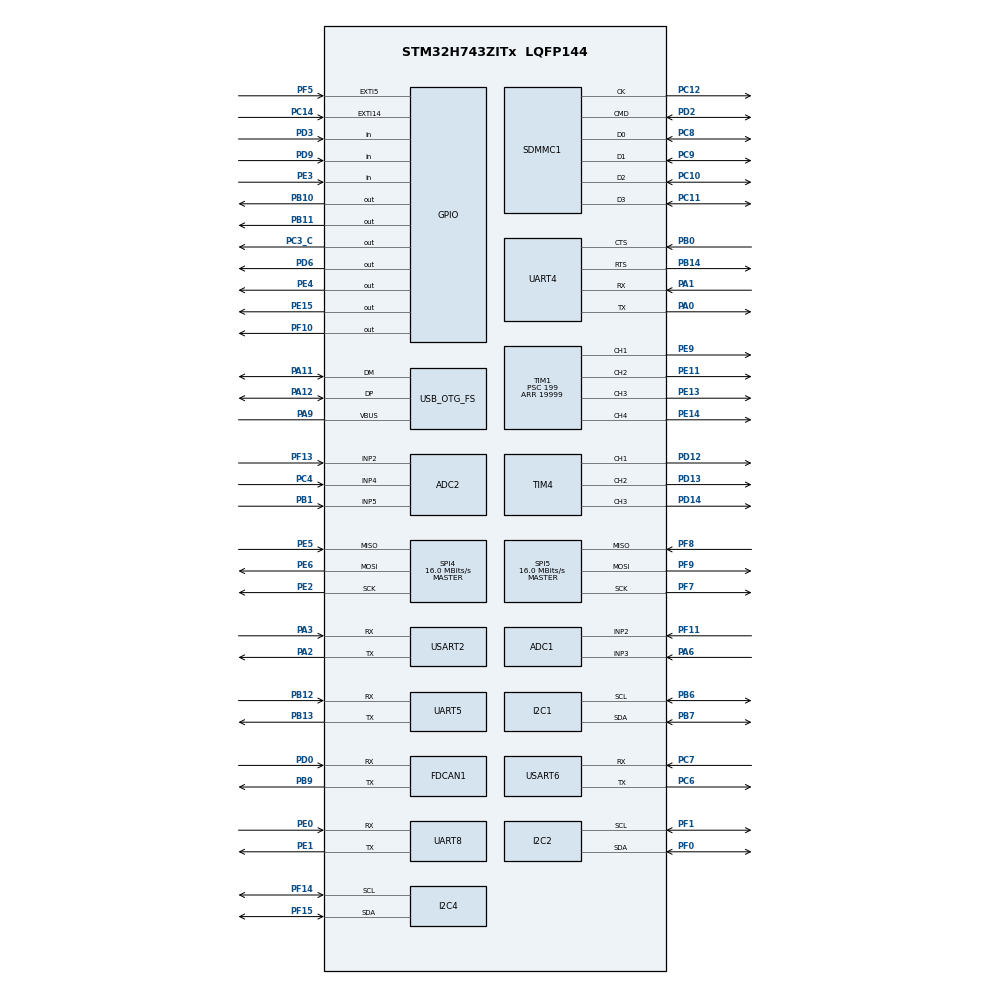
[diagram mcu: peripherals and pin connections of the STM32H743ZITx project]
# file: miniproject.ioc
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ADC1.Channel-3\#ChannelRegularConversion=ADC_CHANNEL_2
ADC1.ClockPrescaler=ADC_CLOCK_ASYNC_DIV4
ADC1.NbrOfConversionFlag=1
ADC1.OffsetNumber-3\#ChannelRegularConversion=ADC_OFFSET_NONE
ADC1.OffsetSignedSaturation-3\#ChannelRegularConversion=DISABLE
ADC1.Rank-3\#ChannelRegularConversion=1
ADC1.SamplingTime-3\#ChannelRegularConversion=ADC_SAMPLETIME_1CYCLE_5
ADC1.master=1
ADC2.Channel-0\#ChannelRegularConversion=ADC_CHANNEL_2
ADC2.ClockPrescaler=ADC_CLOCK_ASYNC_DIV4
ADC2.NbrOfConversionFlag=1
ADC2.OffsetNumber-0\#ChannelRegularConversion=ADC_OFFSET_NONE
ADC2.OffsetSignedSaturation-0\#ChannelRegularConversion=DISABLE
ADC2.Rank-0\#ChannelRegularConversion=1
ADC2.SamplingTime-0\#ChannelRegularConversion=ADC_SAMPLETIME_1CYCLE_5
CORTEX_M7.default_mode_Activation=1
FDCAN1.CalculateBaudRateNominal=1041666
FDCAN1.CalculateTimeBitNominal=960
FDCAN1.CalculateTimeQuantumNominal=320.0
I2C1.Timing=0x00707CBB
I2C2.Timing=0x00707CBB
I2C4.Timing=0x00707CBB
Mcu.Family=STM32H7
Mcu.Name=STM32H743ZITx
Mcu.Package=LQFP144
NVIC.PriorityGroup=NVIC_PRIORITYGROUP_4
PA0.Mode=Asynchronous
PA0.Signal=UART4_TX
PA1.Mode=Asynchronous
PA1.Signal=UART4_RX
PA11.Mode=Device_Only
PA11.Signal=USB_OTG_FS_DM
PA12.Mode=Device_Only
PA12.Signal=USB_OTG_FS_DP
PA13\ (JTMS/SWDIO).Mode=Trace_Asynchronous_SW
PA13\ (JTMS/SWDIO).Signal=DEBUG_JTMS-SWDIO
PA14\ (JTCK/SWCLK).Mode=Trace_Asynchronous_SW
PA14\ (JTCK/SWCLK).Signal=DEBUG_JTCK-SWCLK
PA2.Mode=Asynchronous
PA2.Signal=USART2_TX
PA3.Mode=Asynchronous
PA3.Signal=USART2_RX
PA6.Signal=ADCx_INP3
PA9.Mode=Activate_VBUS
PA9.Signal=USB_OTG_FS_VBUS
PB0.Mode=CTS_RTS
PB0.Signal=UART4_CTS
PB1.Signal=ADCx_INP5
PB10.Signal=GPIO_Output
PB11.Signal=GPIO_Output
PB12.Mode=Asynchronous
PB12.Signal=UART5_RX
PB13.Mode=Asynchronous
PB13.Signal=UART5_TX
PB14.Mode=CTS_RTS
PB14.Signal=UART4_RTS
PB3\ (JTDO/TRACESWO).Mode=Trace_Asynchronous_SW
PB3\ (JTDO/TRACESWO).Signal=DEBUG_JTDO-SWO
PB6.Mode=I2C
PB6.Signal=I2C1_SCL
PB7.Mode=I2C
PB7.Signal=I2C1_SDA
PB9.Mode=FDCAN_Activate
PB9.Signal=FDCAN1_TX
PC10.Mode=SD_4_bits_Wide_bus
PC10.Signal=SDMMC1_D2
PC11.Mode=SD_4_bits_Wide_bus
PC11.Signal=SDMMC1_D3
PC12.Mode=SD_4_bits_Wide_bus
PC12.Signal=SDMMC1_CK
PC14-OSC32_IN\ (OSC32_IN).Signal=GPXTI14
PC3_C.Signal=GPIO_Output
PC4.Signal=ADCx_INP4
PC6.Mode=Asynchronous
PC6.Signal=USART6_TX
PC7.Mode=Asynchronous
PC7.Signal=USART6_RX
PC8.Mode=SD_4_bits_Wide_bus
PC8.Signal=SDMMC1_D0
PC9.Mode=SD_4_bits_Wide_bus
PC9.Signal=SDMMC1_D1
PD0.Mode=FDCAN_Activate
PD0.Signal=FDCAN1_RX
PD12.Signal=S_TIM4_CH1
PD13.Signal=S_TIM4_CH2
PD14.Signal=S_TIM4_CH3
PD2.Mode=SD_4_bits_Wide_bus
PD2.Signal=SDMMC1_CMD
PD3.Signal=GPIO_Input
PD6.Signal=GPIO_Output
PD9.Signal=GPIO_Input
PE0.Mode=Asynchronous
PE0.Signal=UART8_RX
PE1.Mode=Asynchronous
PE1.Signal=UART8_TX
PE11.Signal=S_TIM1_CH2
PE13.Signal=S_TIM1_CH3
PE14.Signal=S_TIM1_CH4
PE15.Signal=GPIO_Output
PE2.Mode=Full_Duplex_Master
PE2.Signal=SPI4_SCK
PE3.Signal=GPIO_Input
PE4.Signal=GPIO_Output
PE5.Mode=Full_Duplex_Master
PE5.Signal=SPI4_MISO
PE6.Mode=Full_Duplex_Master
PE6.Signal=SPI4_MOSI
PE9.Signal=S_TIM1_CH1
PF0.Mode=I2C
PF0.Signal=I2C2_SDA
PF1.Mode=I2C
PF1.Signal=I2C2_SCL
PF10.Signal=GPIO_Output
PF11.Mode=IN2-Single-Ended
PF11.Signal=ADC1_INP2
PF13.Mode=IN2-Single-Ended
PF13.Signal=ADC2_INP2
PF14.Mode=I2C
PF14.Signal=I2C4_SCL
PF15.Mode=I2C
PF15.Signal=I2C4_SDA
PF5.Signal=GPXTI5
PF7.Mode=Full_Duplex_Master
PF7.Signal=SPI5_SCK
PF8.Mode=Full_Duplex_Master
PF8.Signal=SPI5_MISO
PF9.Mode=Full_Duplex_Master
PF9.Signal=SPI5_MOSI
PH0-OSC_IN\ (PH0).Mode=HSE-External-Oscillator
PH0-OSC_IN\ (PH0).Signal=RCC_OSC_IN
PH1-OSC_OUT\ (PH1).Mode=HSE-External-Oscillator
PH1-OSC_OUT\ (PH1).Signal=RCC_OSC_OUT
ProjectManager.HeapSize=0x200
ProjectManager.StackSize=0x400
ProjectManager.TargetToolchain=STM32CubeIDE
RCC.ADCFreq_Value=75000000
RCC.APB1Freq_Value=32000000
RCC.APB2Freq_Value=32000000
RCC.APB3Freq_Value=64000000
RCC.APB4Freq_Value=32000000
RCC.CortexFreq_Value=64000000
RCC.D2PPRE1=RCC_APB1_DIV2
RCC.D2PPRE2=RCC_APB2_DIV2
RCC.D3PPRE=RCC_APB4_DIV2
RCC.DIVM1=2
RCC.DIVM2=2
RCC.DIVN1=12
RCC.DIVN2=12
RCC.DIVQ1=3
RCC.HCLKFreq_Value=64000000
RCC.PLL2FRACN=0
RCC.PLL3FRACN=0
RCC.PLLFRACN=0
RCC.SYSCLKFreq_VALUE=64000000
RCC.USBFreq_Value=50000000
SH.ADCx_INP3.0=ADC1_INP3,IN3-Single-Ended
SH.ADCx_INP4.0=ADC2_INP4,IN4-Single-Ended
SH.ADCx_INP5.0=ADC2_INP5,IN5-Single-Ended
SH.S_TIM1_CH1.0=TIM1_CH1,PWM Generation1 CH1
SH.S_TIM1_CH2.0=TIM1_CH2,PWM Generation2 CH2
SH.S_TIM1_CH3.0=TIM1_CH3,PWM Generation3 CH3
SH.S_TIM1_CH4.0=TIM1_CH4,PWM Generation4 CH4
SH.S_TIM4_CH1.0=TIM4_CH1,PWM Generation1 CH1
SH.S_TIM4_CH2.0=TIM4_CH2,PWM Generation2 CH2
SH.S_TIM4_CH3.0=TIM4_CH3,PWM Generation3 CH3
SPI4.CalculateBaudRate=16.0 MBits/s
SPI4.Direction=SPI_DIRECTION_2LINES
SPI4.Mode=SPI_MODE_MASTER
SPI4.VirtualType=VM_MASTER
SPI5.CalculateBaudRate=16.0 MBits/s
SPI5.Direction=SPI_DIRECTION_2LINES
SPI5.Mode=SPI_MODE_MASTER
SPI5.VirtualType=VM_MASTER
TIM1.AutoReloadPreload=TIM_AUTORELOAD_PRELOAD_ENABLE
TIM1.Channel-PWM\ Generation1\ CH1=TIM_CHANNEL_1
TIM1.Channel-PWM\ Generation2\ CH2=TIM_CHANNEL_2
TIM1.Channel-PWM\ Generation3\ CH3=TIM_CHANNEL_3
TIM1.Channel-PWM\ Generation4\ CH4=TIM_CHANNEL_4
TIM1.Period=19999
TIM1.Prescaler=199
TIM1.Pulse-PWM\ Generation2\ CH2=1000
TIM1.Pulse-PWM\ Generation3\ CH3=1000
TIM1.Pulse-PWM\ Generation4\ CH4=1000
TIM4.Channel-PWM\ Generation1\ CH1=TIM_CHANNEL_1
TIM4.Channel-PWM\ Generation2\ CH2=TIM_CHANNEL_2
TIM4.Channel-PWM\ Generation3\ CH3=TIM_CHANNEL_3
TIM4.OCPolarity_1=TIM_OCPOLARITY_LOW
TIM4.OCPolarity_2=TIM_OCPOLARITY_LOW
TIM4.OCPolarity_3=TIM_OCPOLARITY_LOW
UART8.RxPinLevelInvertParam=UART_ADVFEATURE_RXINV_DISABLE
USART2.VirtualMode-Asynchronous=VM_ASYNC
USART6.VirtualMode-Asynchronous=VM_ASYNC
USB_OTG_FS.VirtualMode=Device_Only
VP_MEMORYMAP_VS_MEMORYMAP.Mode=CurAppReg
VP_TIM1_VS_ClockSourceINT.Mode=Internal
VP_TIM4_VS_ClockSourceINT.Mode=Internal
board=custom

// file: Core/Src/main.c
/* USER CODE BEGIN Header */
/**
  ******************************************************************************
  * @file           : main.c
  * @brief          : Main program body
  ******************************************************************************
  * @attention
  *
  * Copyright (c) 2026 STMicroelectronics.
  * All rights reserved.
  *
  * This software is licensed under terms that can be found in the LICENSE file
  * in the root directory of this software component.
  * If no LICENSE file comes with this software, it is provided AS-IS.
  *
  ******************************************************************************
  */
/* USER CODE END Header */
#include "aquila.h"
#include "main.h"

ADC_HandleTypeDef hadc1;
ADC_HandleTypeDef hadc2;

FDCAN_HandleTypeDef hfdcan1;

I2C_HandleTypeDef hi2c1;
I2C_HandleTypeDef hi2c2;
I2C_HandleTypeDef hi2c4;

SD_HandleTypeDef hsd1;

SPI_HandleTypeDef hspi4;
SPI_HandleTypeDef hspi5;

TIM_HandleTypeDef htim1;
TIM_HandleTypeDef htim4;

UART_HandleTypeDef huart4;
UART_HandleTypeDef huart5;
UART_HandleTypeDef huart8;
UART_HandleTypeDef huart2;
UART_HandleTypeDef huart6;

PCD_HandleTypeDef hpcd_USB_OTG_FS;

void SystemClock_Config(void);
void PeriphCommonClock_Config(void);
static void MPU_Config(void);
static void MX_GPIO_Init(void);
static void MX_USB_OTG_FS_PCD_Init(void);
static void MX_I2C1_Init(void);
static void MX_SDMMC1_SD_Init(void);
static void MX_UART4_Init(void);
static void MX_UART5_Init(void);
static void MX_ADC1_Init(void);
static void MX_I2C2_Init(void);
static void MX_TIM4_Init(void);
static void MX_I2C4_Init(void);
static void MX_TIM1_Init(void);
static void MX_FDCAN1_Init(void);
static void MX_SPI4_Init(void);
static void MX_SPI5_Init(void);
static void MX_UART8_Init(void);
static void MX_ADC2_Init(void);
static void MX_USART2_UART_Init(void);
static void MX_USART6_UART_Init(void);

int main(void)
{

  /* MPU Configuration--------------------------------------------------------*/
  MPU_Config();

  /* MCU Configuration--------------------------------------------------------*/

  /* Reset of all peripherals, Initializes the Flash interface and the Systick. */
  HAL_Init();

  /* Configure the system clock */
  SystemClock_Config();

  /* Configure the peripherals common clocks */
  PeriphCommonClock_Config();

  /* Initialize all configured peripherals */
  MX_GPIO_Init();
  MX_USB_OTG_FS_PCD_Init();
  MX_I2C1_Init();
  MX_SDMMC1_SD_Init();
  MX_UART4_Init();
  MX_UART5_Init();
  MX_ADC1_Init();
  MX_I2C2_Init();
  MX_TIM4_Init();
  MX_I2C4_Init();
  MX_TIM1_Init();
  MX_FDCAN1_Init();
  MX_SPI4_Init();
  MX_SPI5_Init();
  MX_UART8_Init();
  MX_ADC2_Init();
  MX_USART2_UART_Init();
  MX_USART6_UART_Init();
  /* USER CODE BEGIN 2 */
  Aquila_Init();
  /* USER CODE END 2 */

  /* Infinite loop */
  while (1)
  {
	  Aquila_Run();
  }
}

void SystemClock_Config(void)
{
  RCC_OscInitTypeDef RCC_OscInitStruct = {0};
  RCC_ClkInitTypeDef RCC_ClkInitStruct = {0};

  /** Supply configuration update enable
  */
  HAL_PWREx_ConfigSupply(PWR_LDO_SUPPLY);

  /** Configure the main internal regulator output voltage
  */
  __HAL_PWR_VOLTAGESCALING_CONFIG(PWR_REGULATOR_VOLTAGE_SCALE3);

  while(!__HAL_PWR_GET_FLAG(PWR_FLAG_VOSRDY)) {}

  /** Initializes the RCC Oscillators according to the specified parameters
  * in the RCC_OscInitTypeDef structure.
  */
  RCC_OscInitStruct.OscillatorType = RCC_OSCILLATORTYPE_HSI|RCC_OSCILLATORTYPE_HSE;
  RCC_OscInitStruct.HSEState = RCC_HSE_ON;
  RCC_OscInitStruct.HSIState = RCC_HSI_DIV1;
  RCC_OscInitStruct.HSICalibrationValue = RCC_HSICALIBRATION_DEFAULT;
  RCC_OscInitStruct.PLL.PLLState = RCC_PLL_ON;
  RCC_OscInitStruct.PLL.PLLSource = RCC_PLLSOURCE_HSE;
  RCC_OscInitStruct.PLL.PLLM = 2;
  RCC_OscInitStruct.PLL.PLLN = 12;
  RCC_OscInitStruct.PLL.PLLP = 2;
  RCC_OscInitStruct.PLL.PLLQ = 3;
  RCC_OscInitStruct.PLL.PLLR = 2;
  RCC_OscInitStruct.PLL.PLLRGE = RCC_PLL1VCIRANGE_3;
  RCC_OscInitStruct.PLL.PLLVCOSEL = RCC_PLL1VCOMEDIUM;
  RCC_OscInitStruct.PLL.PLLFRACN = 0;
  if (HAL_RCC_OscConfig(&RCC_OscInitStruct) != HAL_OK)
  {
    Error_Handler();
  }

  /** Initializes the CPU, AHB and APB buses clocks
  */
  RCC_ClkInitStruct.ClockType = RCC_CLOCKTYPE_HCLK|RCC_CLOCKTYPE_SYSCLK
                              |RCC_CLOCKTYPE_PCLK1|RCC_CLOCKTYPE_PCLK2
                              |RCC_CLOCKTYPE_D3PCLK1|RCC_CLOCKTYPE_D1PCLK1;
  RCC_ClkInitStruct.SYSCLKSource = RCC_SYSCLKSOURCE_HSI;
  RCC_ClkInitStruct.SYSCLKDivider = RCC_SYSCLK_DIV1;
  RCC_ClkInitStruct.AHBCLKDivider = RCC_HCLK_DIV1;
  RCC_ClkInitStruct.APB3CLKDivider = RCC_APB3_DIV1;
  RCC_ClkInitStruct.APB1CLKDivider = RCC_APB1_DIV2;
  RCC_ClkInitStruct.APB2CLKDivider = RCC_APB2_DIV2;
  RCC_ClkInitStruct.APB4CLKDivider = RCC_APB4_DIV2;

  if (HAL_RCC_ClockConfig(&RCC_ClkInitStruct, FLASH_LATENCY_1) != HAL_OK)
  {
    Error_Handler();
  }
}

void PeriphCommonClock_Config(void)
{
  RCC_PeriphCLKInitTypeDef PeriphClkInitStruct = {0};

  /** Initializes the peripherals clock
  */
  PeriphClkInitStruct.PeriphClockSelection = RCC_PERIPHCLK_ADC;
  PeriphClkInitStruct.PLL2.PLL2M = 2;
  PeriphClkInitStruct.PLL2.PLL2N = 12;
  PeriphClkInitStruct.PLL2.PLL2P = 2;
  PeriphClkInitStruct.PLL2.PLL2Q = 2;
  PeriphClkInitStruct.PLL2.PLL2R = 2;
  PeriphClkInitStruct.PLL2.PLL2RGE = RCC_PLL2VCIRANGE_3;
  PeriphClkInitStruct.PLL2.PLL2VCOSEL = RCC_PLL2VCOMEDIUM;
  PeriphClkInitStruct.PLL2.PLL2FRACN = 0;
  PeriphClkInitStruct.AdcClockSelection = RCC_ADCCLKSOURCE_PLL2;
  if (HAL_RCCEx_PeriphCLKConfig(&PeriphClkInitStruct) != HAL_OK)
  {
    Error_Handler();
  }
}

static void MX_ADC1_Init(void)
{

  ADC_MultiModeTypeDef multimode = {0};
  ADC_ChannelConfTypeDef sConfig = {0};

  /** Common config
  */
  hadc1.Instance = ADC1;
  hadc1.Init.ClockPrescaler = ADC_CLOCK_ASYNC_DIV4;
  hadc1.Init.Resolution = ADC_RESOLUTION_16B;
  hadc1.Init.ScanConvMode = ADC_SCAN_DISABLE;
  hadc1.Init.EOCSelection = ADC_EOC_SINGLE_CONV;
  hadc1.Init.LowPowerAutoWait = DISABLE;
  hadc1.Init.ContinuousConvMode = DISABLE;
  hadc1.Init.NbrOfConversion = 1;
  hadc1.Init.DiscontinuousConvMode = DISABLE;
  hadc1.Init.ExternalTrigConv = ADC_SOFTWARE_START;
  hadc1.Init.ExternalTrigConvEdge = ADC_EXTERNALTRIGCONVEDGE_NONE;
  hadc1.Init.ConversionDataManagement = ADC_CONVERSIONDATA_DR;
  hadc1.Init.Overrun = ADC_OVR_DATA_PRESERVED;
  hadc1.Init.LeftBitShift = ADC_LEFTBITSHIFT_NONE;
  hadc1.Init.OversamplingMode = DISABLE;
  hadc1.Init.Oversampling.Ratio = 1;
  if (HAL_ADC_Init(&hadc1) != HAL_OK)
  {
    Error_Handler();
  }

  /** Configure the ADC multi-mode
  */
  multimode.Mode = ADC_MODE_INDEPENDENT;
  if (HAL_ADCEx_MultiModeConfigChannel(&hadc1, &multimode) != HAL_OK)
  {
    Error_Handler();
  }

  /** Configure Regular Channel
  */
  sConfig.Channel = ADC_CHANNEL_2;
  sConfig.Rank = ADC_REGULAR_RANK_1;
  sConfig.SamplingTime = ADC_SAMPLETIME_1CYCLE_5;
  sConfig.SingleDiff = ADC_SINGLE_ENDED;
  sConfig.OffsetNumber = ADC_OFFSET_NONE;
  sConfig.Offset = 0;
  sConfig.OffsetSignedSaturation = DISABLE;
  if (HAL_ADC_ConfigChannel(&hadc1, &sConfig) != HAL_OK)
  {
    Error_Handler();
  }

}

static void MX_ADC2_Init(void)
{

  ADC_ChannelConfTypeDef sConfig = {0};

  /** Common config
  */
  hadc2.Instance = ADC2;
  hadc2.Init.ClockPrescaler = ADC_CLOCK_ASYNC_DIV4;
  hadc2.Init.Resolution = ADC_RESOLUTION_16B;
  hadc2.Init.ScanConvMode = ADC_SCAN_DISABLE;
  hadc2.Init.EOCSelection = ADC_EOC_SINGLE_CONV;
  hadc2.Init.LowPowerAutoWait = DISABLE;
  hadc2.Init.ContinuousConvMode = DISABLE;
  hadc2.Init.NbrOfConversion = 1;
  hadc2.Init.DiscontinuousConvMode = DISABLE;
  hadc2.Init.ExternalTrigConv = ADC_SOFTWARE_START;
  hadc2.Init.ExternalTrigConvEdge = ADC_EXTERNALTRIGCONVEDGE_NONE;
  hadc2.Init.ConversionDataManagement = ADC_CONVERSIONDATA_DR;
  hadc2.Init.Overrun = ADC_OVR_DATA_PRESERVED;
  hadc2.Init.LeftBitShift = ADC_LEFTBITSHIFT_NONE;
  hadc2.Init.OversamplingMode = DISABLE;
  hadc2.Init.Oversampling.Ratio = 1;
  if (HAL_ADC_Init(&hadc2) != HAL_OK)
  {
    Error_Handler();
  }

  /** Configure Regular Channel
  */
  sConfig.Channel = ADC_CHANNEL_2;
  sConfig.Rank = ADC_REGULAR_RANK_1;
  sConfig.SamplingTime = ADC_SAMPLETIME_1CYCLE_5;
  sConfig.SingleDiff = ADC_SINGLE_ENDED;
  sConfig.OffsetNumber = ADC_OFFSET_NONE;
  sConfig.Offset = 0;
  sConfig.OffsetSignedSaturation = DISABLE;
  if (HAL_ADC_ConfigChannel(&hadc2, &sConfig) != HAL_OK)
  {
    Error_Handler();
  }

}

static void MX_FDCAN1_Init(void)
{

  hfdcan1.Instance = FDCAN1;
  hfdcan1.Init.FrameFormat = FDCAN_FRAME_CLASSIC;
  hfdcan1.Init.Mode = FDCAN_MODE_NORMAL;
  hfdcan1.Init.AutoRetransmission = DISABLE;
  hfdcan1.Init.TransmitPause = DISABLE;
  hfdcan1.Init.ProtocolException = DISABLE;
  hfdcan1.Init.NominalPrescaler = 16;
  hfdcan1.Init.NominalSyncJumpWidth = 1;
  hfdcan1.Init.NominalTimeSeg1 = 1;
  hfdcan1.Init.NominalTimeSeg2 = 1;
  hfdcan1.Init.DataPrescaler = 1;
  hfdcan1.Init.DataSyncJumpWidth = 1;
  hfdcan1.Init.DataTimeSeg1 = 1;
  hfdcan1.Init.DataTimeSeg2 = 1;
  hfdcan1.Init.MessageRAMOffset = 0;
  hfdcan1.Init.StdFiltersNbr = 0;
  hfdcan1.Init.ExtFiltersNbr = 0;
  hfdcan1.Init.RxFifo0ElmtsNbr = 0;
  hfdcan1.Init.RxFifo0ElmtSize = FDCAN_DATA_BYTES_8;
  hfdcan1.Init.RxFifo1ElmtsNbr = 0;
  hfdcan1.Init.RxFifo1ElmtSize = FDCAN_DATA_BYTES_8;
  hfdcan1.Init.RxBuffersNbr = 0;
  hfdcan1.Init.RxBufferSize = FDCAN_DATA_BYTES_8;
  hfdcan1.Init.TxEventsNbr = 0;
  hfdcan1.Init.TxBuffersNbr = 0;
  hfdcan1.Init.TxFifoQueueElmtsNbr = 0;
  hfdcan1.Init.TxFifoQueueMode = FDCAN_TX_FIFO_OPERATION;
  hfdcan1.Init.TxElmtSize = FDCAN_DATA_BYTES_8;
  if (HAL_FDCAN_Init(&hfdcan1) != HAL_OK)
  {
    Error_Handler();
  }

}

static void MX_I2C1_Init(void)
{

  hi2c1.Instance = I2C1;
  hi2c1.Init.Timing = 0x00707CBB;
  hi2c1.Init.OwnAddress1 = 0;
  hi2c1.Init.AddressingMode = I2C_ADDRESSINGMODE_7BIT;
  hi2c1.Init.DualAddressMode = I2C_DUALADDRESS_DISABLE;
  hi2c1.Init.OwnAddress2 = 0;
  hi2c1.Init.OwnAddress2Masks = I2C_OA2_NOMASK;
  hi2c1.Init.GeneralCallMode = I2C_GENERALCALL_DISABLE;
  hi2c1.Init.NoStretchMode = I2C_NOSTRETCH_DISABLE;
  if (HAL_I2C_Init(&hi2c1) != HAL_OK)
  {
    Error_Handler();
  }

  /** Configure Analogue filter
  */
  if (HAL_I2CEx_ConfigAnalogFilter(&hi2c1, I2C_ANALOGFILTER_ENABLE) != HAL_OK)
  {
    Error_Handler();
  }

  /** Configure Digital filter
  */
  if (HAL_I2CEx_ConfigDigitalFilter(&hi2c1, 0) != HAL_OK)
  {
    Error_Handler();
  }

}

static void MX_I2C2_Init(void)
{

  hi2c2.Instance = I2C2;
  hi2c2.Init.Timing = 0x00707CBB;
  hi2c2.Init.OwnAddress1 = 0;
  hi2c2.Init.AddressingMode = I2C_ADDRESSINGMODE_7BIT;
  hi2c2.Init.DualAddressMode = I2C_DUALADDRESS_DISABLE;
  hi2c2.Init.OwnAddress2 = 0;
  hi2c2.Init.OwnAddress2Masks = I2C_OA2_NOMASK;
  hi2c2.Init.GeneralCallMode = I2C_GENERALCALL_DISABLE;
  hi2c2.Init.NoStretchMode = I2C_NOSTRETCH_DISABLE;
  if (HAL_I2C_Init(&hi2c2) != HAL_OK)
  {
    Error_Handler();
  }

  /** Configure Analogue filter
  */
  if (HAL_I2CEx_ConfigAnalogFilter(&hi2c2, I2C_ANALOGFILTER_ENABLE) != HAL_OK)
  {
    Error_Handler();
  }

  /** Configure Digital filter
  */
  if (HAL_I2CEx_ConfigDigitalFilter(&hi2c2, 0) != HAL_OK)
  {
    Error_Handler();
  }

}

static void MX_I2C4_Init(void)
{

  hi2c4.Instance = I2C4;
  hi2c4.Init.Timing = 0x00707CBB;
  hi2c4.Init.OwnAddress1 = 0;
  hi2c4.Init.AddressingMode = I2C_ADDRESSINGMODE_7BIT;
  hi2c4.Init.DualAddressMode = I2C_DUALADDRESS_DISABLE;
  hi2c4.Init.OwnAddress2 = 0;
  hi2c4.Init.OwnAddress2Masks = I2C_OA2_NOMASK;
  hi2c4.Init.GeneralCallMode = I2C_GENERALCALL_DISABLE;
  hi2c4.Init.NoStretchMode = I2C_NOSTRETCH_DISABLE;
  if (HAL_I2C_Init(&hi2c4) != HAL_OK)
  {
    Error_Handler();
  }

  /** Configure Analogue filter
  */
  if (HAL_I2CEx_ConfigAnalogFilter(&hi2c4, I2C_ANALOGFILTER_ENABLE) != HAL_OK)
  {
    Error_Handler();
  }

  /** Configure Digital filter
  */
  if (HAL_I2CEx_ConfigDigitalFilter(&hi2c4, 0) != HAL_OK)
  {
    Error_Handler();
  }

}

static void MX_SDMMC1_SD_Init(void)
{

  hsd1.Instance = SDMMC1;
  hsd1.Init.ClockEdge = SDMMC_CLOCK_EDGE_RISING;
  hsd1.Init.ClockPowerSave = SDMMC_CLOCK_POWER_SAVE_DISABLE;
  hsd1.Init.BusWide = SDMMC_BUS_WIDE_4B;
  hsd1.Init.HardwareFlowControl = SDMMC_HARDWARE_FLOW_CONTROL_DISABLE;
  hsd1.Init.ClockDiv = 0;
  if (HAL_SD_Init(&hsd1) != HAL_OK)
  {
    Error_Handler();
  }

}

static void MX_SPI4_Init(void)
{

  /* SPI4 parameter configuration*/
  hspi4.Instance = SPI4;
  hspi4.Init.Mode = SPI_MODE_MASTER;
  hspi4.Init.Direction = SPI_DIRECTION_2LINES;
  hspi4.Init.DataSize = SPI_DATASIZE_4BIT;
  hspi4.Init.CLKPolarity = SPI_POLARITY_LOW;
  hspi4.Init.CLKPhase = SPI_PHASE_1EDGE;
  hspi4.Init.NSS = SPI_NSS_SOFT;
  hspi4.Init.BaudRatePrescaler = SPI_BAUDRATEPRESCALER_2;
  hspi4.Init.FirstBit = SPI_FIRSTBIT_MSB;
  hspi4.Init.TIMode = SPI_TIMODE_DISABLE;
  hspi4.Init.CRCCalculation = SPI_CRCCALCULATION_DISABLE;
  hspi4.Init.CRCPolynomial = 0x0;
  hspi4.Init.NSSPMode = SPI_NSS_PULSE_ENABLE;
  hspi4.Init.NSSPolarity = SPI_NSS_POLARITY_LOW;
  hspi4.Init.FifoThreshold = SPI_FIFO_THRESHOLD_01DATA;
  hspi4.Init.TxCRCInitializationPattern = SPI_CRC_INITIALIZATION_ALL_ZERO_PATTERN;
  hspi4.Init.RxCRCInitializationPattern = SPI_CRC_INITIALIZATION_ALL_ZERO_PATTERN;
  hspi4.Init.MasterSSIdleness = SPI_MASTER_SS_IDLENESS_00CYCLE;
  hspi4.Init.MasterInterDataIdleness = SPI_MASTER_INTERDATA_IDLENESS_00CYCLE;
  hspi4.Init.MasterReceiverAutoSusp = SPI_MASTER_RX_AUTOSUSP_DISABLE;
  hspi4.Init.MasterKeepIOState = SPI_MASTER_KEEP_IO_STATE_DISABLE;
  hspi4.Init.IOSwap = SPI_IO_SWAP_DISABLE;
  if (HAL_SPI_Init(&hspi4) != HAL_OK)
  {
    Error_Handler();
  }

}

static void MX_SPI5_Init(void)
{

  /* SPI5 parameter configuration*/
  hspi5.Instance = SPI5;
  hspi5.Init.Mode = SPI_MODE_MASTER;
  hspi5.Init.Direction = SPI_DIRECTION_2LINES;
  hspi5.Init.DataSize = SPI_DATASIZE_4BIT;
  hspi5.Init.CLKPolarity = SPI_POLARITY_LOW;
  hspi5.Init.CLKPhase = SPI_PHASE_1EDGE;
  hspi5.Init.NSS = SPI_NSS_SOFT;
  hspi5.Init.BaudRatePrescaler = SPI_BAUDRATEPRESCALER_2;
  hspi5.Init.FirstBit = SPI_FIRSTBIT_MSB;
  hspi5.Init.TIMode = SPI_TIMODE_DISABLE;
  hspi5.Init.CRCCalculation = SPI_CRCCALCULATION_DISABLE;
  hspi5.Init.CRCPolynomial = 0x0;
  hspi5.Init.NSSPMode = SPI_NSS_PULSE_ENABLE;
  hspi5.Init.NSSPolarity = SPI_NSS_POLARITY_LOW;
  hspi5.Init.FifoThreshold = SPI_FIFO_THRESHOLD_01DATA;
  hspi5.Init.TxCRCInitializationPattern = SPI_CRC_INITIALIZATION_ALL_ZERO_PATTERN;
  hspi5.Init.RxCRCInitializationPattern = SPI_CRC_INITIALIZATION_ALL_ZERO_PATTERN;
  hspi5.Init.MasterSSIdleness = SPI_MASTER_SS_IDLENESS_00CYCLE;
  hspi5.Init.MasterInterDataIdleness = SPI_MASTER_INTERDATA_IDLENESS_00CYCLE;
  hspi5.Init.MasterReceiverAutoSusp = SPI_MASTER_RX_AUTOSUSP_DISABLE;
  hspi5.Init.MasterKeepIOState = SPI_MASTER_KEEP_IO_STATE_DISABLE;
  hspi5.Init.IOSwap = SPI_IO_SWAP_DISABLE;
  if (HAL_SPI_Init(&hspi5) != HAL_OK)
  {
    Error_Handler();
  }

}

static void MX_TIM1_Init(void)
{

  TIM_ClockConfigTypeDef sClockSourceConfig = {0};
  TIM_MasterConfigTypeDef sMasterConfig = {0};
  TIM_OC_InitTypeDef sConfigOC = {0};
  TIM_BreakDeadTimeConfigTypeDef sBreakDeadTimeConfig = {0};

  htim1.Instance = TIM1;
  htim1.Init.Prescaler = 199;
  htim1.Init.CounterMode = TIM_COUNTERMODE_UP;
  htim1.Init.Period = 19999;
  htim1.Init.ClockDivision = TIM_CLOCKDIVISION_DIV1;
  htim1.Init.RepetitionCounter = 0;
  htim1.Init.AutoReloadPreload = TIM_AUTORELOAD_PRELOAD_ENABLE;
  if (HAL_TIM_Base_Init(&htim1) != HAL_OK)
  {
    Error_Handler();
  }
  sClockSourceConfig.ClockSource = TIM_CLOCKSOURCE_INTERNAL;
  if (HAL_TIM_ConfigClockSource(&htim1, &sClockSourceConfig) != HAL_OK)
  {
    Error_Handler();
  }
  if (HAL_TIM_PWM_Init(&htim1) != HAL_OK)
  {
    Error_Handler();
  }
  sMasterConfig.MasterOutputTrigger = TIM_TRGO_RESET;
  sMasterConfig.MasterOutputTrigger2 = TIM_TRGO2_RESET;
  sMasterConfig.MasterSlaveMode = TIM_MASTERSLAVEMODE_DISABLE;
  if (HAL_TIMEx_MasterConfigSynchronization(&htim1, &sMasterConfig) != HAL_OK)
  {
    Error_Handler();
  }
  sConfigOC.OCMode = TIM_OCMODE_PWM1;
  sConfigOC.Pulse = 0;
  sConfigOC.OCPolarity = TIM_OCPOLARITY_HIGH;
  sConfigOC.OCNPolarity = TIM_OCNPOLARITY_HIGH;
  sConfigOC.OCFastMode = TIM_OCFAST_DISABLE;
  sConfigOC.OCIdleState = TIM_OCIDLESTATE_RESET;
  sConfigOC.OCNIdleState = TIM_OCNIDLESTATE_RESET;
  if (HAL_TIM_PWM_ConfigChannel(&htim1, &sConfigOC, TIM_CHANNEL_1) != HAL_OK)
  {
    Error_Handler();
  }
  sConfigOC.Pulse = 1000;
  if (HAL_TIM_PWM_ConfigChannel(&htim1, &sConfigOC, TIM_CHANNEL_2) != HAL_OK)
  {
    Error_Handler();
  }
  if (HAL_TIM_PWM_ConfigChannel(&htim1, &sConfigOC, TIM_CHANNEL_3) != HAL_OK)
  {
    Error_Handler();
  }
  if (HAL_TIM_PWM_ConfigChannel(&htim1, &sConfigOC, TIM_CHANNEL_4) != HAL_OK)
  {
    Error_Handler();
  }
  sBreakDeadTimeConfig.OffStateRunMode = TIM_OSSR_DISABLE;
  sBreakDeadTimeConfig.OffStateIDLEMode = TIM_OSSI_DISABLE;
  sBreakDeadTimeConfig.LockLevel = TIM_LOCKLEVEL_OFF;
  sBreakDeadTimeConfig.DeadTime = 0;
  sBreakDeadTimeConfig.BreakState = TIM_BREAK_DISABLE;
  sBreakDeadTimeConfig.BreakPolarity = TIM_BREAKPOLARITY_HIGH;
  sBreakDeadTimeConfig.BreakFilter = 0;
  sBreakDeadTimeConfig.Break2State = TIM_BREAK2_DISABLE;
  sBreakDeadTimeConfig.Break2Polarity = TIM_BREAK2POLARITY_HIGH;
  sBreakDeadTimeConfig.Break2Filter = 0;
  sBreakDeadTimeConfig.AutomaticOutput = TIM_AUTOMATICOUTPUT_DISABLE;
  if (HAL_TIMEx_ConfigBreakDeadTime(&htim1, &sBreakDeadTimeConfig) != HAL_OK)
  {
    Error_Handler();
  }
  HAL_TIM_MspPostInit(&htim1);

}

static void MX_TIM4_Init(void)
{

  TIM_ClockConfigTypeDef sClockSourceConfig = {0};
  TIM_MasterConfigTypeDef sMasterConfig = {0};
  TIM_OC_InitTypeDef sConfigOC = {0};

  htim4.Instance = TIM4;
  htim4.Init.Prescaler = 0;
  htim4.Init.CounterMode = TIM_COUNTERMODE_UP;
  htim4.Init.Period = 65535;
  htim4.Init.ClockDivision = TIM_CLOCKDIVISION_DIV1;
  htim4.Init.AutoReloadPreload = TIM_AUTORELOAD_PRELOAD_DISABLE;
  if (HAL_TIM_Base_Init(&htim4) != HAL_OK)
  {
    Error_Handler();
  }
  sClockSourceConfig.ClockSource = TIM_CLOCKSOURCE_INTERNAL;
  if (HAL_TIM_ConfigClockSource(&htim4, &sClockSourceConfig) != HAL_OK)
  {
    Error_Handler();
  }
  if (HAL_TIM_PWM_Init(&htim4) != HAL_OK)
  {
    Error_Handler();
  }
  sMasterConfig.MasterOutputTrigger = TIM_TRGO_RESET;
  sMasterConfig.MasterSlaveMode = TIM_MASTERSLAVEMODE_DISABLE;
  if (HAL_TIMEx_MasterConfigSynchronization(&htim4, &sMasterConfig) != HAL_OK)
  {
    Error_Handler();
  }
  sConfigOC.OCMode = TIM_OCMODE_PWM1;
  sConfigOC.Pulse = 0;
  sConfigOC.OCPolarity = TIM_OCPOLARITY_LOW;
  sConfigOC.OCFastMode = TIM_OCFAST_DISABLE;
  if (HAL_TIM_PWM_ConfigChannel(&htim4, &sConfigOC, TIM_CHANNEL_1) != HAL_OK)
  {
    Error_Handler();
  }
  if (HAL_TIM_PWM_ConfigChannel(&htim4, &sConfigOC, TIM_CHANNEL_2) != HAL_OK)
  {
    Error_Handler();
  }
  if (HAL_TIM_PWM_ConfigChannel(&htim4, &sConfigOC, TIM_CHANNEL_3) != HAL_OK)
  {
    Error_Handler();
  }
  HAL_TIM_MspPostInit(&htim4);

}

static void MX_UART4_Init(void)
{

  huart4.Instance = UART4;
  huart4.Init.BaudRate = 115200;
  huart4.Init.WordLength = UART_WORDLENGTH_8B;
  huart4.Init.StopBits = UART_STOPBITS_1;
  huart4.Init.Parity = UART_PARITY_NONE;
  huart4.Init.Mode = UART_MODE_TX_RX;
  huart4.Init.HwFlowCtl = UART_HWCONTROL_RTS_CTS;
  huart4.Init.OverSampling = UART_OVERSAMPLING_16;
  huart4.Init.OneBitSampling = UART_ONE_BIT_SAMPLE_DISABLE;
  huart4.Init.ClockPrescaler = UART_PRESCALER_DIV1;
  huart4.AdvancedInit.AdvFeatureInit = UART_ADVFEATURE_NO_INIT;
  if (HAL_UART_Init(&huart4) != HAL_OK)
  {
    Error_Handler();
  }
  if (HAL_UARTEx_SetTxFifoThreshold(&huart4, UART_TXFIFO_THRESHOLD_1_8) != HAL_OK)
  {
    Error_Handler();
  }
  if (HAL_UARTEx_SetRxFifoThreshold(&huart4, UART_RXFIFO_THRESHOLD_1_8) != HAL_OK)
  {
    Error_Handler();
  }
  if (HAL_UARTEx_DisableFifoMode(&huart4) != HAL_OK)
  {
    Error_Handler();
  }

}

static void MX_UART5_Init(void)
{

  huart5.Instance = UART5;
  huart5.Init.BaudRate = 115200;
  huart5.Init.WordLength = UART_WORDLENGTH_8B;
  huart5.Init.StopBits = UART_STOPBITS_1;
  huart5.Init.Parity = UART_PARITY_NONE;
  huart5.Init.Mode = UART_MODE_TX_RX;
  huart5.Init.HwFlowCtl = UART_HWCONTROL_NONE;
  huart5.Init.OverSampling = UART_OVERSAMPLING_16;
  huart5.Init.OneBitSampling = UART_ONE_BIT_SAMPLE_DISABLE;
  huart5.Init.ClockPrescaler = UART_PRESCALER_DIV1;
  huart5.AdvancedInit.AdvFeatureInit = UART_ADVFEATURE_NO_INIT;
  if (HAL_UART_Init(&huart5) != HAL_OK)
  {
    Error_Handler();
  }
  if (HAL_UARTEx_SetTxFifoThreshold(&huart5, UART_TXFIFO_THRESHOLD_1_8) != HAL_OK)
  {
    Error_Handler();
  }
  if (HAL_UARTEx_SetRxFifoThreshold(&huart5, UART_RXFIFO_THRESHOLD_1_8) != HAL_OK)
  {
    Error_Handler();
  }
  if (HAL_UARTEx_DisableFifoMode(&huart5) != HAL_OK)
  {
    Error_Handler();
  }

}

static void MX_UART8_Init(void)
{

  huart8.Instance = UART8;
  huart8.Init.BaudRate = 115200;
  huart8.Init.WordLength = UART_WORDLENGTH_8B;
  huart8.Init.StopBits = UART_STOPBITS_1;
  huart8.Init.Parity = UART_PARITY_NONE;
  huart8.Init.Mode = UART_MODE_TX_RX;
  huart8.Init.HwFlowCtl = UART_HWCONTROL_NONE;
  huart8.Init.OverSampling = UART_OVERSAMPLING_16;
  huart8.Init.OneBitSampling = UART_ONE_BIT_SAMPLE_DISABLE;
  huart8.Init.ClockPrescaler = UART_PRESCALER_DIV1;
  huart8.AdvancedInit.AdvFeatureInit = UART_ADVFEATURE_NO_INIT;
  if (HAL_UART_Init(&huart8) != HAL_OK)
  {
    Error_Handler();
  }
  if (HAL_UARTEx_SetTxFifoThreshold(&huart8, UART_TXFIFO_THRESHOLD_1_8) != HAL_OK)
  {
    Error_Handler();
  }
  if (HAL_UARTEx_SetRxFifoThreshold(&huart8, UART_RXFIFO_THRESHOLD_1_8) != HAL_OK)
  {
    Error_Handler();
  }
  if (HAL_UARTEx_DisableFifoMode(&huart8) != HAL_OK)
  {
    Error_Handler();
  }

}

static void MX_USART2_UART_Init(void)
{

  huart2.Instance = USART2;
  huart2.Init.BaudRate = 115200;
  huart2.Init.WordLength = UART_WORDLENGTH_8B;
  huart2.Init.StopBits = UART_STOPBITS_1;
  huart2.Init.Parity = UART_PARITY_NONE;
  huart2.Init.Mode = UART_MODE_TX_RX;
  huart2.Init.HwFlowCtl = UART_HWCONTROL_NONE;
  huart2.Init.OverSampling = UART_OVERSAMPLING_16;
  huart2.Init.OneBitSampling = UART_ONE_BIT_SAMPLE_DISABLE;
  huart2.Init.ClockPrescaler = UART_PRESCALER_DIV1;
  huart2.AdvancedInit.AdvFeatureInit = UART_ADVFEATURE_NO_INIT;
  if (HAL_UART_Init(&huart2) != HAL_OK)
  {
    Error_Handler();
  }
  if (HAL_UARTEx_SetTxFifoThreshold(&huart2, UART_TXFIFO_THRESHOLD_1_8) != HAL_OK)
  {
    Error_Handler();
  }
  if (HAL_UARTEx_SetRxFifoThreshold(&huart2, UART_RXFIFO_THRESHOLD_1_8) != HAL_OK)
  {
    Error_Handler();
  }
  if (HAL_UARTEx_DisableFifoMode(&huart2) != HAL_OK)
  {
    Error_Handler();
  }

}

static void MX_USART6_UART_Init(void)
{

  huart6.Instance = USART6;
  huart6.Init.BaudRate = 115200;
  huart6.Init.WordLength = UART_WORDLENGTH_8B;
  huart6.Init.StopBits = UART_STOPBITS_1;
  huart6.Init.Parity = UART_PARITY_NONE;
  huart6.Init.Mode = UART_MODE_TX_RX;
  huart6.Init.HwFlowCtl = UART_HWCONTROL_NONE;
  huart6.Init.OverSampling = UART_OVERSAMPLING_16;
  huart6.Init.OneBitSampling = UART_ONE_BIT_SAMPLE_DISABLE;
  huart6.Init.ClockPrescaler = UART_PRESCALER_DIV1;
  huart6.AdvancedInit.AdvFeatureInit = UART_ADVFEATURE_NO_INIT;
  if (HAL_UART_Init(&huart6) != HAL_OK)
  {
    Error_Handler();
  }
  if (HAL_UARTEx_SetTxFifoThreshold(&huart6, UART_TXFIFO_THRESHOLD_1_8) != HAL_OK)
  {
    Error_Handler();
  }
  if (HAL_UARTEx_SetRxFifoThreshold(&huart6, UART_RXFIFO_THRESHOLD_1_8) != HAL_OK)
  {
    Error_Handler();
  }
  if (HAL_UARTEx_DisableFifoMode(&huart6) != HAL_OK)
  {
    Error_Handler();
  }

}

static void MX_USB_OTG_FS_PCD_Init(void)
{

  hpcd_USB_OTG_FS.Instance = USB_OTG_FS;
  hpcd_USB_OTG_FS.Init.dev_endpoints = 9;
  hpcd_USB_OTG_FS.Init.speed = PCD_SPEED_FULL;
  hpcd_USB_OTG_FS.Init.dma_enable = DISABLE;
  hpcd_USB_OTG_FS.Init.phy_itface = PCD_PHY_EMBEDDED;
  hpcd_USB_OTG_FS.Init.Sof_enable = DISABLE;
  hpcd_USB_OTG_FS.Init.low_power_enable = DISABLE;
  hpcd_USB_OTG_FS.Init.lpm_enable = DISABLE;
  hpcd_USB_OTG_FS.Init.battery_charging_enable = ENABLE;
  hpcd_USB_OTG_FS.Init.vbus_sensing_enable = ENABLE;
  hpcd_USB_OTG_FS.Init.use_dedicated_ep1 = DISABLE;
  if (HAL_PCD_Init(&hpcd_USB_OTG_FS) != HAL_OK)
  {
    Error_Handler();
  }

}

static void MX_GPIO_Init(void)
{
  GPIO_InitTypeDef GPIO_InitStruct = {0};

  /* GPIO Ports Clock Enable */
  __HAL_RCC_GPIOE_CLK_ENABLE();
  __HAL_RCC_GPIOC_CLK_ENABLE();
  __HAL_RCC_GPIOF_CLK_ENABLE();
  __HAL_RCC_GPIOH_CLK_ENABLE();
  __HAL_RCC_GPIOA_CLK_ENABLE();
  __HAL_RCC_GPIOB_CLK_ENABLE();
  __HAL_RCC_GPIOD_CLK_ENABLE();

  /*Configure GPIO pin Output Level */
  HAL_GPIO_WritePin(GPIOE, GPIO_PIN_4|GPIO_PIN_15, GPIO_PIN_RESET);

  /*Configure GPIO pin Output Level */
  HAL_GPIO_WritePin(GPIOF, GPIO_PIN_10, GPIO_PIN_RESET);

  /*Configure GPIO pin Output Level */
  HAL_GPIO_WritePin(GPIOC, GPIO_PIN_3, GPIO_PIN_RESET);

  /*Configure GPIO pin Output Level */
  HAL_GPIO_WritePin(GPIOB, GPIO_PIN_10|GPIO_PIN_11, GPIO_PIN_RESET);

  /*Configure GPIO pin Output Level */
  HAL_GPIO_WritePin(GPIOD, GPIO_PIN_6, GPIO_PIN_RESET);

  /*Configure GPIO pin : PE3 */
  GPIO_InitStruct.Pin = GPIO_PIN_3;
  GPIO_InitStruct.Mode = GPIO_MODE_INPUT;
  GPIO_InitStruct.Pull = GPIO_NOPULL;
  HAL_GPIO_Init(GPIOE, &GPIO_InitStruct);

  /*Configure GPIO pins : PE4 PE15 */
  GPIO_InitStruct.Pin = GPIO_PIN_4|GPIO_PIN_15;
  GPIO_InitStruct.Mode = GPIO_MODE_OUTPUT_PP;
  GPIO_InitStruct.Pull = GPIO_NOPULL;
  GPIO_InitStruct.Speed = GPIO_SPEED_FREQ_LOW;
  HAL_GPIO_Init(GPIOE, &GPIO_InitStruct);

  /*Configure GPIO pin : PC14 */
  GPIO_InitStruct.Pin = GPIO_PIN_14;
  GPIO_InitStruct.Mode = GPIO_MODE_IT_RISING;
  GPIO_InitStruct.Pull = GPIO_NOPULL;
  HAL_GPIO_Init(GPIOC, &GPIO_InitStruct);

  /*Configure GPIO pin : PF5 */
  GPIO_InitStruct.Pin = GPIO_PIN_5;
  GPIO_InitStruct.Mode = GPIO_MODE_IT_RISING;
  GPIO_InitStruct.Pull = GPIO_NOPULL;
  HAL_GPIO_Init(GPIOF, &GPIO_InitStruct);

  /*Configure GPIO pin : PF10 */
  GPIO_InitStruct.Pin = GPIO_PIN_10;
  GPIO_InitStruct.Mode = GPIO_MODE_OUTPUT_PP;
  GPIO_InitStruct.Pull = GPIO_NOPULL;
  GPIO_InitStruct.Speed = GPIO_SPEED_FREQ_LOW;
  HAL_GPIO_Init(GPIOF, &GPIO_InitStruct);

  /*Configure GPIO pin : PC3 */
  GPIO_InitStruct.Pin = GPIO_PIN_3;
  GPIO_InitStruct.Mode = GPIO_MODE_OUTPUT_PP;
  GPIO_InitStruct.Pull = GPIO_NOPULL;
  GPIO_InitStruct.Speed = GPIO_SPEED_FREQ_LOW;
  HAL_GPIO_Init(GPIOC, &GPIO_InitStruct);

  /*Configure GPIO pins : PB10 PB11 */
  GPIO_InitStruct.Pin = GPIO_PIN_10|GPIO_PIN_11;
  GPIO_InitStruct.Mode = GPIO_MODE_OUTPUT_PP;
  GPIO_InitStruct.Pull = GPIO_NOPULL;
  GPIO_InitStruct.Speed = GPIO_SPEED_FREQ_LOW;
  HAL_GPIO_Init(GPIOB, &GPIO_InitStruct);

  /*Configure GPIO pins : PD9 PD3 */
  GPIO_InitStruct.Pin = GPIO_PIN_9|GPIO_PIN_3;
  GPIO_InitStruct.Mode = GPIO_MODE_INPUT;
  GPIO_InitStruct.Pull = GPIO_NOPULL;
  HAL_GPIO_Init(GPIOD, &GPIO_InitStruct);

  /*Configure GPIO pin : PD6 */
  GPIO_InitStruct.Pin = GPIO_PIN_6;
  GPIO_InitStruct.Mode = GPIO_MODE_OUTPUT_PP;
  GPIO_InitStruct.Pull = GPIO_NOPULL;
  GPIO_InitStruct.Speed = GPIO_SPEED_FREQ_LOW;
  HAL_GPIO_Init(GPIOD, &GPIO_InitStruct);

  /*AnalogSwitch Config */
  HAL_SYSCFG_AnalogSwitchConfig(SYSCFG_SWITCH_PC3, SYSCFG_SWITCH_PC3_CLOSE);

}

 /* MPU Configuration */

void MPU_Config(void)
{
  MPU_Region_InitTypeDef MPU_InitStruct = {0};

  /* Disables the MPU */
  HAL_MPU_Disable();

  /** Initializes and configures the Region and the memory to be protected
  */
  MPU_InitStruct.Enable = MPU_REGION_ENABLE;
  MPU_InitStruct.Number = MPU_REGION_NUMBER0;
  MPU_InitStruct.BaseAddress = 0x0;
  MPU_InitStruct.Size = MPU_REGION_SIZE_4GB;
  MPU_InitStruct.SubRegionDisable = 0x87;
  MPU_InitStruct.TypeExtField = MPU_TEX_LEVEL0;
  MPU_InitStruct.AccessPermission = MPU_REGION_NO_ACCESS;
  MPU_InitStruct.DisableExec = MPU_INSTRUCTION_ACCESS_DISABLE;
  MPU_InitStruct.IsShareable = MPU_ACCESS_SHAREABLE;
  MPU_InitStruct.IsCacheable = MPU_ACCESS_NOT_CACHEABLE;
  MPU_InitStruct.IsBufferable = MPU_ACCESS_NOT_BUFFERABLE;

  HAL_MPU_ConfigRegion(&MPU_InitStruct);
  /* Enables the MPU */
  HAL_MPU_Enable(MPU_PRIVILEGED_DEFAULT);

}

void Error_Handler(void)
{
  __disable_irq();
  while (1)
  {
  }
}
